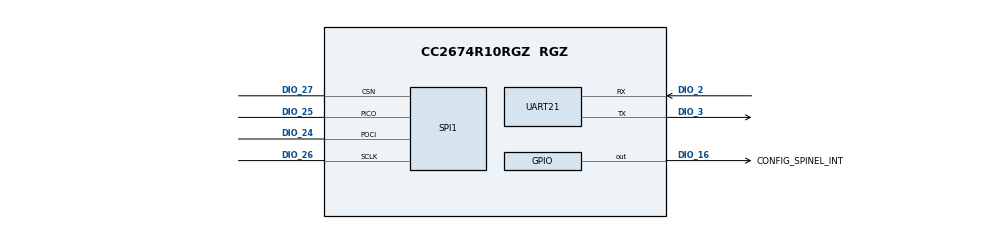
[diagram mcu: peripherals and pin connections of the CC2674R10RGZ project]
/**
 * These arguments were used when this file was generated. They will be automatically applied on subsequent loads
 * via the GUI or CLI. Run CLI with '--help' for additional information on how to override these arguments.
 * @cliArgs --device "CC2674R10RGZ" --package "RGZ" --part "Default" --rtos "freertos" --product "simplelink_cc13xx_cc26xx_sdk@7.10.01.24"
 * @versions {"tool":"1.16.2+3028"}
 */

/**
 * Import the modules used in this configuration.
 */
const CCFG      = scripting.addModule("/ti/devices/CCFG");
const custom    = scripting.addModule("/ti/devices/radioconfig/custom");
const rfdesign  = scripting.addModule("/ti/devices/radioconfig/rfdesign");
const AESECB    = scripting.addModule("/ti/drivers/AESECB");
const AESECB1   = AESECB.addInstance();
const DMA       = scripting.addModule("/ti/drivers/DMA");
const ECDH      = scripting.addModule("/ti/drivers/ECDH");
const ECDH1     = ECDH.addInstance();
const ECDSA     = scripting.addModule("/ti/drivers/ECDSA");
const ECDSA1    = ECDSA.addInstance();
const ECJPAKE   = scripting.addModule("/ti/drivers/ECJPAKE");
const ECJPAKE1  = ECJPAKE.addInstance();
const GPIO      = scripting.addModule("/ti/drivers/GPIO");
const GPIO1     = GPIO.addInstance();
const GPIO2     = GPIO.addInstance();
const GPIO3     = GPIO.addInstance();
const GPIO4     = GPIO.addInstance();
const GPIO5     = GPIO.addInstance();
const NVS       = scripting.addModule("/ti/drivers/NVS");
const NVS1      = NVS.addInstance();
const Power     = scripting.addModule("/ti/drivers/Power");
const RF        = scripting.addModule("/ti/drivers/RF");
const SHA2      = scripting.addModule("/ti/drivers/SHA2");
const SHA21     = SHA2.addInstance();
const SPI       = scripting.addModule("/ti/drivers/SPI");
const SPI1      = SPI.addInstance();
const TRNG      = scripting.addModule("/ti/drivers/TRNG");
const TRNG1     = TRNG.addInstance();
const UART2     = scripting.addModule("/ti/drivers/UART2");
const UART21    = UART2.addInstance();
const Watchdog  = scripting.addModule("/ti/drivers/Watchdog");
const Watchdog1 = Watchdog.addInstance();

/**
 * Write custom configuration values to the imported modules.
 */
CCFG.xoscCapArrayDelta       = 0xD5;
CCFG.enableBootloader        = true;
CCFG.dioBootloaderBackdoor   = 15;
CCFG.levelBootloaderBackdoor = "Active low";
CCFG.srcClkLF                = "Derived from HF XOSC";
CCFG.ccfgTemplate.$name      = "ti_devices_CCFG_CCFGCC26XXTemplate0";

custom.ieee                                                  = ["ieee154"];
custom.radioConfigieee154.$name                              = "ti_devices_radioconfig_settings_ieee_15_40";
custom.radioConfigieee154.codeExportConfig.$name             = "ti_devices_radioconfig_code_export_param0";
custom.radioConfigieee154.codeExportConfig.useConst          = true;
custom.radioConfigieee154.codeExportConfig.useMulti          = true;
custom.radioConfigieee154.codeExportConfig.symGenMethod      = "Custom";
custom.radioConfigieee154.codeExportConfig.cmdList_ieee_15_4 = ["cmdFs","cmdIeeeCsma","cmdIeeeEdScan","cmdIeeeRx","cmdIeeeRxAck","cmdIeeeTx","cmdRadioSetup","cmdTxTest"];
custom.radioConfigieee154.codeExportConfig.cmdRadioSetup     = "RF_cmdIeeeRadioSetup";

AESECB1.$name = "CONFIG_AESECB_MBEDTLS";

ECDH1.$name = "CONFIG_ECDH_0";

ECDSA1.$name = "CONFIG_ECDSA_0";

ECJPAKE1.$name = "CONFIG_ECJPAKE_0";

GPIO1.$name = "CONFIG_GPIO_BTN1";

GPIO2.$name = "CONFIG_GPIO_BTN2";

GPIO3.mode  = "Output";
GPIO3.$name = "CONFIG_GPIO_GLED";

GPIO4.mode  = "Output";
GPIO4.$name = "CONFIG_GPIO_RLED";

GPIO5.$name              = "CONFIG_SPINEL_INT";
GPIO5.mode               = "Output";
GPIO5.outputStrength     = "High";
GPIO5.initialOutputState = "High";
GPIO5.gpioPin.$assign    = "DIO_16";

NVS1.$name                    = "CONFIG_NVSINTERNAL";
NVS1.internalFlash.$name      = "ti_drivers_nvs_NVSCC26XX0";
NVS1.internalFlash.regionBase = 0x52000;
NVS1.internalFlash.regionSize = 0x4000;

SHA21.$name = "CONFIG_SHA2_0";

SPI1.$name               = "CONFIG_SPI_1";
SPI1.mode                = "Four Pin CS Active Low";
SPI1.spi.sclkPin.$assign = "DIO_26";
SPI1.spi.pociPin.$assign = "DIO_24";
SPI1.spi.picoPin.$assign = "DIO_25";
SPI1.spi.csnPin.$assign  = "DIO_27";

TRNG1.$name = "CONFIG_TRNG_THREAD";

UART21.$name              = "CONFIG_UART2_0";
UART21.uart.$assign       = "UART0";
UART21.uart.txPin.$assign = "DIO_3";
UART21.uart.rxPin.$assign = "DIO_2";

Watchdog1.$name            = "CONFIG_WATCHDOG0";
Watchdog1.watchdog.$assign = "WDT0";

/**
 * Pinmux solution for unlocked pins/peripherals. This ensures that minor changes to the automatic solver in a future
 * version of the tool will not impact the pinmux you originally saw.  These lines can be completely deleted in order to
 * re-solve from scratch.
 */
GPIO1.gpioPin.$suggestSolution         = "DIO_0";
GPIO2.gpioPin.$suggestSolution         = "DIO_1";
GPIO3.gpioPin.$suggestSolution         = "DIO_4";
GPIO4.gpioPin.$suggestSolution         = "DIO_5";
SPI1.spi.$suggestSolution              = "SPI0";
SPI1.spi.dmaRxChannel.$suggestSolution = "DMA_CH3";
SPI1.spi.dmaTxChannel.$suggestSolution = "DMA_CH4";
